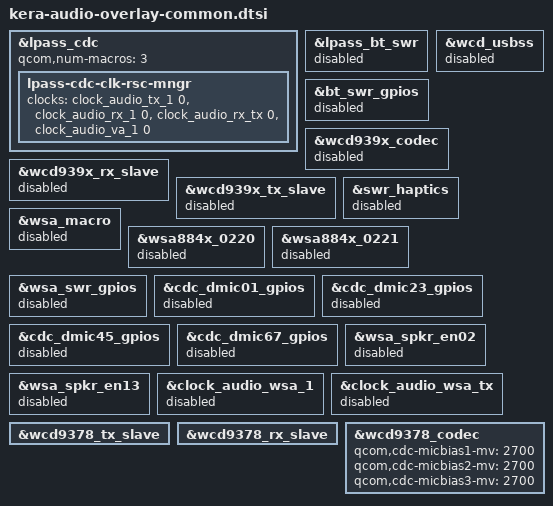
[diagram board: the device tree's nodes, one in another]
&lpass_cdc {
	qcom,num-macros = <3>;
	lpass-cdc-clk-rsc-mngr {
		clock-names = "tx_core_clk", "rx_core_clk", "rx_tx_core_clk", "va_core_clk";
		clocks = <&clock_audio_tx_1 0>, <&clock_audio_rx_1 0>,
			<&clock_audio_rx_tx 0>, <&clock_audio_va_1 0>;
	};
};

&lpass_bt_swr {
	status = "disabled";
};

&bt_swr_gpios {
	status = "disabled";
};

&wcd_usbss {
	status = "disabled";
};

&wcd939x_codec {
	status = "disabled";
};

&wcd939x_rx_slave {
	status = "disabled";
};

&wcd939x_tx_slave {
	status = "disabled";
};

&swr_haptics {
	status = "disabled";
};

&wsa_macro{
    status = "disabled";
};

&wsa884x_0220{
    status = "disabled";
};

&wsa884x_0221{
    status = "disabled";
};

&wsa_swr_gpios {
	status = "disabled";
};

&cdc_dmic01_gpios{
    status = "disabled";
};

&cdc_dmic23_gpios{
    status = "disabled";
};

&cdc_dmic45_gpios{
    status = "disabled";
};

&cdc_dmic67_gpios{
    status = "disabled";
};

&wsa_spkr_en02{
    status = "disabled";
};

&wsa_spkr_en13 {
	status = "disabled";
};

&clock_audio_wsa_1 {
	status = "disabled";
};

&clock_audio_wsa_tx {
	status = "disabled";
};

&wcd9378_tx_slave{
    status = "okay";
};

&wcd9378_rx_slave{
    status = "okay";
};

&wcd9378_codec{
    status = "okay";
    qcom,cdc-micbias1-mv = <2700>;
    qcom,cdc-micbias2-mv = <2700>;
    qcom,cdc-micbias3-mv = <2700>;
};
